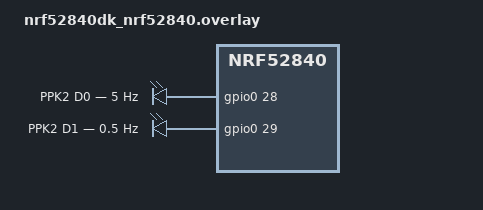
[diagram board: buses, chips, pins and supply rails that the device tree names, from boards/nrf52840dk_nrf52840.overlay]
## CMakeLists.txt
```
cmake_minimum_required(VERSION 3.20.0)
find_package(Zephyr REQUIRED HINTS $ENV{ZEPHYR_BASE})
project(bench_dut LANGUAGES C)

target_sources(app PRIVATE src/main.c)
```

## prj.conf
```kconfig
# nRF54LM20 PPK2 bench DUT — minimal Zephyr config.
#
# GPIO output for the two PPK2 logic channels; everything else is
# pruned so the binary is small and the current trace is dominated
# by the toggle activity itself rather than incidental subsystems.

CONFIG_GPIO=y

# Logging / console — off. We don't want UART traffic competing for
# CPU time while the timers fire, and there's nothing for a human
# to read.
CONFIG_LOG=n
CONFIG_PRINTK=n
CONFIG_BOOT_BANNER=n
CONFIG_CONSOLE=n
CONFIG_SERIAL=n
CONFIG_UART_CONSOLE=n

# Power management — leave defaults. Zephyr's PM idles the CPU
# between timer events, which is what we want for a clean trace.
```

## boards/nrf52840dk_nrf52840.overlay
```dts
/*
 * nRF52840 DK (PCA10056) PPK2 bench-DUT pin assignment.
 *
 * P0.28 → PPK2 D0 (5 Hz square wave)   — Arduino header A2
 * P0.29 → PPK2 D1 (0.5 Hz square wave) — Arduino header A3
 *
 * Both pins sit on the Arduino R3 analog header and are unclaimed
 * in the default board DTS: P0.29 appears only in the disabled spi0
 * pinctrl group ("cannot be used together with i2c0"); the enabled
 * spi1 uses P0.31/P0.30/P1.08. Same pin pair a sibling benchmark
 * validated for its energy-trace instrumentation (chosen there
 * after a PCA10056 schematic check).
 */

/ {
	ppk2_signals {
		compatible = "gpio-leds";

		ppk2_d0: ppk2_d0 {
			gpios = <&gpio0 28 GPIO_ACTIVE_HIGH>;
			label = "PPK2 D0 — 5 Hz";
		};

		ppk2_d1: ppk2_d1 {
			gpios = <&gpio0 29 GPIO_ACTIVE_HIGH>;
			label = "PPK2 D1 — 0.5 Hz";
		};
	};

	aliases {
		ppk2-d0 = &ppk2_d0;
		ppk2-d1 = &ppk2_d1;
	};
};
```

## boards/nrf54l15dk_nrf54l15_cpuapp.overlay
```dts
/*
 * nRF54L15DK (PCA10156) PPK2 bench-DUT pin assignment.
 *
 * P1.11 → PPK2 D0 (5 Hz square wave)
 * P1.12 → PPK2 D1 (0.5 Hz square wave)
 *
 * Both pins are routed to the DK's GPIO connectors (HW User Guide
 * 4503_209, "Connector interface") and are unclaimed in the default
 * board DTS: P1.11 appears only in the disabled spi22 pinctrl group,
 * P1.12 nowhere. LEDs (P2.09/P1.10/P2.07/P1.14), buttons
 * (P1.13/P1.09/P1.08/P0.04) and the uart20 console (P1.04-P1.07)
 * are deliberately avoided.
 */

/ {
	ppk2_signals {
		compatible = "gpio-leds";

		ppk2_d0: ppk2_d0 {
			gpios = <&gpio1 11 GPIO_ACTIVE_HIGH>;
			label = "PPK2 D0 — 5 Hz";
		};

		ppk2_d1: ppk2_d1 {
			gpios = <&gpio1 12 GPIO_ACTIVE_HIGH>;
			label = "PPK2 D1 — 0.5 Hz";
		};
	};

	aliases {
		ppk2-d0 = &ppk2_d0;
		ppk2-d1 = &ppk2_d1;
	};
};
```

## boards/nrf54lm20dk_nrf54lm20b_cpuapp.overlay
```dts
/*
 * nRF54LM20DK PPK2 bench-DUT pin assignment.
 *
 * P1.12 → PPK2 D0 (5 Hz square wave)
 * P1.13 → PPK2 D1 (0.5 Hz square wave)
 *
 * Both pins live on the Arduino-compatible expansion headers and
 * are validated against this DK revision (same pair used by a
 * sibling benchmark project for its energy trace pins).
 */

/ {
	ppk2_signals {
		compatible = "gpio-leds";

		ppk2_d0: ppk2_d0 {
			gpios = <&gpio1 12 GPIO_ACTIVE_HIGH>;
			label = "PPK2 D0 — 5 Hz";
		};

		ppk2_d1: ppk2_d1 {
			gpios = <&gpio1 13 GPIO_ACTIVE_HIGH>;
			label = "PPK2 D1 — 0.5 Hz";
		};
	};

	aliases {
		ppk2-d0 = &ppk2_d0;
		ppk2-d1 = &ppk2_d1;
	};
};
```

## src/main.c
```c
/*
 * nRF54LM20 PPK2 bench-DUT.
 *
 * Toggles two GPIOs at fixed rates so the PPK2's logic channels see
 * a deterministic reference signal during HIL captures:
 *
 *   D0 — 5 Hz   (toggle every 100 ms → 200 ms period, 50 % duty)
 *   D1 — 0.5 Hz (toggle every 1000 ms → 2 s period,   50 % duty)
 *
 * Two Zephyr kernel timers fire from the system tick — toggles run in
 * ISR context so there's no scheduler jitter on the edge timing. The
 * main thread sleeps forever once the timers are armed.
 */

#include <errno.h>
#include <zephyr/device.h>
#include <zephyr/drivers/gpio.h>
#include <zephyr/kernel.h>

#define D0_NODE DT_ALIAS(ppk2_d0)
#define D1_NODE DT_ALIAS(ppk2_d1)

#if !DT_NODE_EXISTS(D0_NODE) || !DT_NODE_EXISTS(D1_NODE)
#error "Both ppk2-d0 and ppk2-d1 aliases must be defined in the board overlay."
#endif

static const struct gpio_dt_spec d0 = GPIO_DT_SPEC_GET(D0_NODE, gpios);
static const struct gpio_dt_spec d1 = GPIO_DT_SPEC_GET(D1_NODE, gpios);

/* Half-periods (timers fire on every toggle). */
#define D0_HALF_PERIOD K_MSEC(100)
#define D1_HALF_PERIOD K_MSEC(1000)

static void d0_toggle(struct k_timer *timer)
{
	ARG_UNUSED(timer);
	(void)gpio_pin_toggle_dt(&d0);
}

static void d1_toggle(struct k_timer *timer)
{
	ARG_UNUSED(timer);
	(void)gpio_pin_toggle_dt(&d1);
}

K_TIMER_DEFINE(d0_timer, d0_toggle, NULL);
K_TIMER_DEFINE(d1_timer, d1_toggle, NULL);

int main(void)
{
	if (!gpio_is_ready_dt(&d0) || !gpio_is_ready_dt(&d1)) {
		return -ENODEV;
	}

	int err = gpio_pin_configure_dt(&d0, GPIO_OUTPUT_INACTIVE);
	if (err) {
		return err;
	}
	err = gpio_pin_configure_dt(&d1, GPIO_OUTPUT_INACTIVE);
	if (err) {
		return err;
	}

	/* Start both timers with zero initial delay so the first toggle
	 * lands one half-period from boot. Period == half-period because
	 * the timer callback toggles the pin every fire. */
	k_timer_start(&d0_timer, D0_HALF_PERIOD, D0_HALF_PERIOD);
	k_timer_start(&d1_timer, D1_HALF_PERIOD, D1_HALF_PERIOD);

	for (;;) {
		k_sleep(K_FOREVER);
	}
	return 0;
}
```
